# LargeDummyDevice register map
File version: 1.0
Registers are 32-bit, read-write, no defined reset value unless marked. A register's access mark holds for its fields unless they carry their own. Offsets are from the block's base; [hi:lo] are bit positions.

## PERIPHERAL_91
Base 0x4005A000
0x04 REG_1 — Register 1
  [34:30] FIELD_7, [28:24] FIELD_5, [26:24] FIELD_14, [24:20] FIELD_3, [23:20] FIELD_4, [21:20] FIELD_15, [23:20] FIELD_17, [20:18] FIELD_2, [22:18] FIELD_6, [18:17] FIELD_16, [21:17] FIELD_18, [20:16] FIELD_19, [16:15] FIELD_10, [15:11] FIELD_1, [7:6] FIELD_8, [6] FIELD_9, [6] FIELD_12, [8:4] FIELD_13, [3:2] FIELD_11
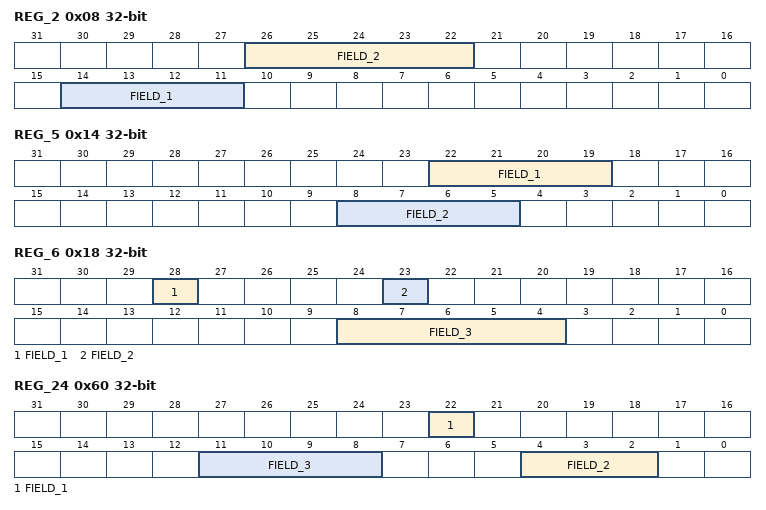
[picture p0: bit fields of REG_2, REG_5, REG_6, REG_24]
0x08 REG_2 — Register 2
  [26:22] FIELD_2, [14:11] FIELD_1
0x0C REG_3 — Register 3
  [31:30] FIELD_19, [31:29] FIELD_10, [30:29] FIELD_22, [29:27] FIELD_21, [24:21] FIELD_11, [25:21] FIELD_13, [21:20] FIELD_3, [18:16] FIELD_1, [16] FIELD_18, [14] FIELD_6, [13] FIELD_9, [12] FIELD_12, [13:9] FIELD_20, [12:8] FIELD_2, [6] FIELD_4, [8:6] FIELD_7, [7:6] FIELD_8, [5] FIELD_16, [5:4] FIELD_14, [2:1] FIELD_15, [4:1] FIELD_17, [4:0] FIELD_5
0x10 REG_4 — Register 4
  [34:30] FIELD_2, [32:29] FIELD_7, [32:29] FIELD_15, [30:27] FIELD_9, [26] FIELD_11, [27:25] FIELD_8, [22:18] FIELD_1, [20:16] FIELD_10, [16:15] FIELD_3, [15:14] FIELD_4, [14] FIELD_12, [13:12] FIELD_6, [3] FIELD_5, [7:3] FIELD_13, [2:1] FIELD_14
0x14 REG_5 — Register 5
  [22:19] FIELD_1, [8:5] FIELD_2
0x18 REG_6 — Register 6
  [28] FIELD_1, [23] FIELD_2, [8:4] FIELD_3
0x1C REG_7 — Register 7
  [32:31] FIELD_3, [31:29] FIELD_6, [28:27] FIELD_5, [29:25] FIELD_12, [21] FIELD_2, [18:17] FIELD_1, [12] FIELD_11, [10] FIELD_4, [14:10] FIELD_8, [10] FIELD_9, [5:1] FIELD_10, [1:0] FIELD_7
0x20 REG_8 — Register 8
  [34:31] FIELD_5, [29:28] FIELD_14, [32:28] FIELD_22, [26] FIELD_4, [25:22] FIELD_11, [25:21] FIELD_15, [23:19] FIELD_20, [21:17] FIELD_1, [15] FIELD_18, [19:15] FIELD_21, [16:12] FIELD_2, [13:12] FIELD_25, [13:11] FIELD_6, [13:11] FIELD_13, [13:10] FIELD_12, [11:10] FIELD_23, [10:8] FIELD_16, [8:6] FIELD_7, [5] FIELD_8, [5:4] FIELD_24, [4:3] FIELD_9, [4:3] FIELD_10, [5:3] FIELD_17, [4:1] FIELD_19, [4:0] FIELD_3
0x24 REG_9 — Register 9
  [29:28] FIELD_5, [28:27] FIELD_14, [24] FIELD_2, [27:24] FIELD_12, [24:22] FIELD_1, [21] FIELD_7, [21:20] FIELD_11, [22:20] FIELD_15, [21:19] FIELD_13, [21:18] FIELD_6, [18] FIELD_17, [18:17] FIELD_9, [15:11] FIELD_8, [12:11] FIELD_10, [12:10] FIELD_16, [5:3] FIELD_3, [5:2] FIELD_4
0x28 REG_10 — Register 10
  [28] FIELD_3, [27:24] FIELD_1, [16:15] FIELD_5, [14:10] FIELD_2, [11:8] FIELD_4
0x2C REG_11 — Register 11
  [32:31] FIELD_16, [31] FIELD_21, [32:28] FIELD_7, [26] FIELD_8, [23:21] FIELD_10, [20:18] FIELD_13, [21:17] FIELD_3, [21:17] FIELD_20, [14:13] FIELD_2, [13] FIELD_12, [13] FIELD_18, [15:12] FIELD_5, [15:12] FIELD_15, [15:11] FIELD_4, [14:10] FIELD_11, [10] FIELD_14, [13:9] FIELD_6, [9:8] FIELD_1, [9:7] FIELD_9, [5] FIELD_17, [5] FIELD_22, [4] FIELD_19
0x30 REG_12 — Register 12
  [32:31] FIELD_4, [32:31] FIELD_14, [31:30] FIELD_5, [29] FIELD_10, [33:29] FIELD_18, [30:26] FIELD_2, [26:24] FIELD_11, [25:23] FIELD_20, [25:22] FIELD_27, [24:21] FIELD_24, [21:19] FIELD_15, [20:19] FIELD_23, [17] FIELD_28, [18:15] FIELD_16, [15:12] FIELD_9, [11:10] FIELD_1, [10:7] FIELD_8, [11:7] FIELD_12, [6] FIELD_3, [8:5] FIELD_7, [6:5] FIELD_13, [8:5] FIELD_22, [8:4] FIELD_17, [7:3] FIELD_26, [3:2] FIELD_21, [4:1] FIELD_19, [4:1] FIELD_25, [0] FIELD_6
0x34 REG_13 — Register 13
  [14] FIELD_1
0x38 REG_14 — Register 14
  [32:29] FIELD_15, [28:25] FIELD_3, [23] FIELD_6, [20] FIELD_11, [22:19] FIELD_4, [16] FIELD_9, [15] FIELD_13, [15:14] FIELD_8, [16:14] FIELD_12, [13] FIELD_5, [12:11] FIELD_7, [8] FIELD_1, [9:8] FIELD_16, [6:5] FIELD_2, [8:5] FIELD_10, [3:2] FIELD_14
0x3C REG_15 — Register 15
  [29:28] FIELD_8, [28:27] FIELD_13, [24:23] FIELD_4, [23] FIELD_7, [21:19] FIELD_15, [18:17] FIELD_3, [19:17] FIELD_12, [21:17] FIELD_14, [20:16] FIELD_5, [16:14] FIELD_9, [15:11] FIELD_10, [10] FIELD_11, [8] FIELD_1, [7:6] FIELD_2, [4:0] FIELD_6
0x40 REG_16 — Register 16
  [31:30] FIELD_1, [33:30] FIELD_11, [30] FIELD_17, [26] FIELD_6, [26:22] FIELD_5, [23:22] FIELD_14, [19:17] FIELD_4, [21:17] FIELD_12, [15:12] FIELD_7, [12:10] FIELD_10, [9] FIELD_15, [12:8] FIELD_8, [9:8] FIELD_16, [8:7] FIELD_3, [11:7] FIELD_13, [4:3] FIELD_2, [5:1] FIELD_9
0x44 REG_17 — Register 17
  [32:31] FIELD_9, [27:26] FIELD_15, [28:25] FIELD_1, [28:24] FIELD_25, [23] FIELD_8, [20] FIELD_10, [21:18] FIELD_24, [19:17] FIELD_23, [18:15] FIELD_11, [19:15] FIELD_17, [15:13] FIELD_4, [12] FIELD_12, [15:11] FIELD_14, [11] FIELD_19, [13:10] FIELD_3, [12:10] FIELD_20, [11:9] FIELD_2, [9] FIELD_5, [10:8] FIELD_7, [9:7] FIELD_21, [7:6] FIELD_16, [8:4] FIELD_6, [6:3] FIELD_13, [4:1] FIELD_18, [1:0] FIELD_22
0x48 REG_18 — Register 18
  [29:28] FIELD_15, [30:27] FIELD_3, [26:25] FIELD_5, [24:23] FIELD_8, [21:17] FIELD_12, [16:15] FIELD_7, [19:15] FIELD_11, [12] FIELD_1, [12:11] FIELD_2, [8] FIELD_4, [10:6] FIELD_6, [9:6] FIELD_9, [7:6] FIELD_14, [8:4] FIELD_13, [4:2] FIELD_10
0x4C REG_19 — Register 19
  [27:26] FIELD_1
0x50 REG_20 — Register 20
  [33:31] FIELD_22, [34:30] FIELD_14, [32:28] FIELD_16, [31:27] FIELD_7, [30:27] FIELD_8, [28:27] FIELD_12, [26:23] FIELD_2, [27:23] FIELD_20, [23:22] FIELD_18, [23:22] FIELD_25, [22:20] FIELD_3, [20] FIELD_6, [23:20] FIELD_9, [19:15] FIELD_24, [14] FIELD_5, [14:13] FIELD_1, [12:11] FIELD_4, [13:9] FIELD_11, [7] FIELD_15, [7] FIELD_21, [7:6] FIELD_13, [8:5] FIELD_23, [6:4] FIELD_19, [3:1] FIELD_17, [2:0] FIELD_10
0x54 REG_21 — Register 21
  [24] FIELD_2, [24:21] FIELD_3, [14:10] FIELD_1
0x58 REG_22 — Register 22
  [34:31] FIELD_13, [31:30] FIELD_17, [33:29] FIELD_12, [29:26] FIELD_6, [30:26] FIELD_18, [28:25] FIELD_2, [26:24] FIELD_7, [26:24] FIELD_9, [25:21] FIELD_3, [19:17] FIELD_11, [19:16] FIELD_16, [14] FIELD_1, [16:12] FIELD_5, [11:10] FIELD_14, [10:6] FIELD_19, [2:1] FIELD_8, [0] FIELD_4, [0] FIELD_10, [3:0] FIELD_15
0x5C REG_23 — Register 23
  [30:28] FIELD_2, [28:27] FIELD_5, [30:27] FIELD_10, [29:25] FIELD_13, [25:21] FIELD_9, [21:20] FIELD_7, [24:20] FIELD_17, [20] FIELD_22, [18] FIELD_8, [18] FIELD_23, [12] FIELD_19, [14:11] FIELD_1, [13:9] FIELD_14, [11:8] FIELD_6, [6] FIELD_3, [8:6] FIELD_12, [6:5] FIELD_4, [5] FIELD_18, [4] FIELD_11, [6:4] FIELD_16, [8:4] FIELD_21, [7:3] FIELD_20, [2:0] FIELD_15
0x60 REG_24 — Register 24
  [22] FIELD_1, [11:8] FIELD_3, [4:2] FIELD_2
0x64 REG_25 — Register 25
  [32:31] FIELD_1, [31:30] FIELD_14, [32:29] FIELD_8, [32:29] FIELD_20, [28] FIELD_11, [30:28] FIELD_17, [25] FIELD_15, [23:21] FIELD_9, [21] FIELD_10, [22:21] FIELD_19, [25:21] FIELD_22, [23:19] FIELD_4, [20:19] FIELD_12, [19:17] FIELD_2, [21:17] FIELD_25, [18:16] FIELD_3, [15:14] FIELD_5, [14] FIELD_7, [15:12] FIELD_6, [14:12] FIELD_21, [11] FIELD_24, [12:10] FIELD_23, [10:6] FIELD_13, [7:6] FIELD_16, [8:4] FIELD_18
0x68 REG_26 — Register 26
  [34:31] FIELD_2, [33:31] FIELD_9, [30] FIELD_8, [34:30] FIELD_20, [31:27] FIELD_10, [28:25] FIELD_11, [27:24] FIELD_25, [25:23] FIELD_29, [24:20] FIELD_4, [23:19] FIELD_30, [22:18] FIELD_15, [20:18] FIELD_17, [18] FIELD_28, [20:17] FIELD_22, [19:16] FIELD_1, [20:16] FIELD_12, [17:16] FIELD_21, [17:16] FIELD_26, [15] FIELD_6, [14] FIELD_23, [11:10] FIELD_5, [10] FIELD_14, [10:9] FIELD_13, [9:8] FIELD_16, [7:6] FIELD_27, [4] FIELD_18, [2:1] FIELD_3, [5:1] FIELD_24, [1:0] FIELD_7, [3:0] FIELD_19
0x6C REG_27 — Register 27
  [32:30] FIELD_26, [29:28] FIELD_11, [27:25] FIELD_9, [26:25] FIELD_17, [24:23] FIELD_6, [24:23] FIELD_20, [22] FIELD_13, [22:20] FIELD_22, [20:19] FIELD_25, [15] FIELD_14, [18:14] FIELD_18, [13:12] FIELD_4, [15:11] FIELD_10, [11:8] FIELD_7, [9:7] FIELD_5, [10:7] FIELD_15, [10:6] FIELD_1, [7:4] FIELD_2, [7:4] FIELD_8, [7:4] FIELD_12, [4:2] FIELD_24, [5:1] FIELD_3, [2:1] FIELD_16, [2:1] FIELD_19, [0] FIELD_21, [1:0] FIELD_23
0x70 REG_28 — Register 28
  [30] FIELD_11, [26:25] FIELD_15, [25:24] FIELD_1, [25:24] FIELD_7, [25:23] FIELD_5, [23] FIELD_22, [24:21] FIELD_2, [22:21] FIELD_23, [22:20] FIELD_19, [23:19] FIELD_17, [18:17] FIELD_20, [17] FIELD_24, [21:17] FIELD_25, [18:15] FIELD_12, [15:13] FIELD_4, [16:13] FIELD_10, [13:11] FIELD_16, [11:8] FIELD_9, [12:8] FIELD_18, [11:7] FIELD_26, [6:4] FIELD_6, [8:4] FIELD_14, [4:3] FIELD_21, [2] FIELD_3, [3:2] FIELD_13, [5:1] FIELD_8
0x74 REG_29 — Register 29
  [28] FIELD_1, [19:17] FIELD_5, [8] FIELD_4, [12:8] FIELD_6, [7:6] FIELD_3, [6:3] FIELD_9, [4:2] FIELD_2, [2:1] FIELD_7, [0] FIELD_8
0x78 REG_30 — Register 30
  [29:27] FIELD_3, [27:26] FIELD_7, [27:25] FIELD_14, [27:24] FIELD_6, [22:20] FIELD_13, [21:19] FIELD_1, [18:17] FIELD_11, [18:15] FIELD_8, [19:15] FIELD_9, [15:14] FIELD_5, [9:8] FIELD_10, [7:4] FIELD_12, [4:2] FIELD_2, [1:0] FIELD_4
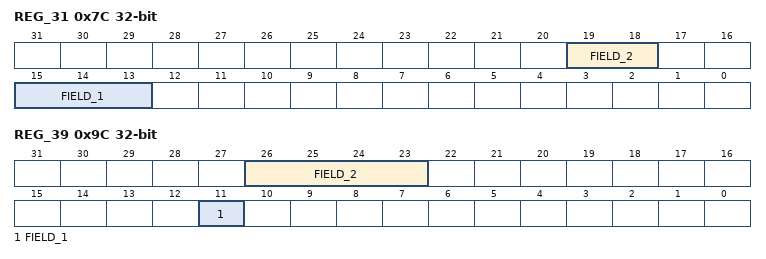
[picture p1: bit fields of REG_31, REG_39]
0x7C REG_31 — Register 31
  [19:18] FIELD_2, [15:13] FIELD_1
0x80 REG_32 — Register 32
  [11:9] FIELD_1
0x84 REG_33 — Register 33
  [30:27] FIELD_9, [30:26] FIELD_11, [29:25] FIELD_25, [26:23] FIELD_3, [25:23] FIELD_24, [26:22] FIELD_5, [24:22] FIELD_7, [23:22] FIELD_15, [20] FIELD_8, [15:13] FIELD_2, [15:13] FIELD_17, [13] FIELD_19, [14:12] FIELD_16, [16:12] FIELD_22, [13:10] FIELD_12, [11:9] FIELD_4, [8] FIELD_20, [7] FIELD_1, [7] FIELD_13, [7:5] FIELD_6, [6:4] FIELD_18, [5:4] FIELD_23, [5:3] FIELD_14, [3:1] FIELD_10, [2:1] FIELD_21
0x88 REG_34 — Register 34
  [34:30] FIELD_12, [32:28] FIELD_23, [31:27] FIELD_14, [30:27] FIELD_19, [30:26] FIELD_27, [26:25] FIELD_9, [26:25] FIELD_18, [25:24] FIELD_25, [25:23] FIELD_4, [24:23] FIELD_16, [26:23] FIELD_21, [27:23] FIELD_24, [25:22] FIELD_1, [23:22] FIELD_17, [26:22] FIELD_22, [23:21] FIELD_3, [22:21] FIELD_15, [20] FIELD_7, [21:19] FIELD_5, [22:18] FIELD_13, [19:17] FIELD_11, [18:16] FIELD_26, [18:14] FIELD_8, [5] FIELD_2, [9:5] FIELD_20, [5:4] FIELD_6, [3:0] FIELD_10
0x8C REG_35 — Register 35
  [33:29] FIELD_13, [32:28] FIELD_20, [28:27] FIELD_17, [29:27] FIELD_18, [29:27] FIELD_22, [25] FIELD_11, [25:24] FIELD_10, [23:22] FIELD_15, [24:22] FIELD_16, [19] FIELD_6, [19] FIELD_8, [21:17] FIELD_3, [16:15] FIELD_12, [16:14] FIELD_2, [17:14] FIELD_4, [17:13] FIELD_23, [15:12] FIELD_9, [12:11] FIELD_19, [12:10] FIELD_14, [9] FIELD_5, [9:7] FIELD_1, [9:7] FIELD_7, [10:7] FIELD_21
0x90 REG_36 — Register 36
  [33:31] FIELD_1, [34:31] FIELD_20, [31:30] FIELD_3, [30:28] FIELD_10, [24:23] FIELD_12, [24:22] FIELD_13, [22:21] FIELD_14, [20:18] FIELD_16, [16] FIELD_8, [16] FIELD_9, [18:14] FIELD_11, [13:11] FIELD_17, [11:10] FIELD_6, [8] FIELD_18, [7] FIELD_4, [10:6] FIELD_2, [8:6] FIELD_7, [6:4] FIELD_5, [6:4] FIELD_15, [5:2] FIELD_19
0x94 REG_37 — Register 37
  [35:31] FIELD_18, [33:29] FIELD_5, [29:26] FIELD_12, [24] FIELD_4, [25:23] FIELD_9, [27:23] FIELD_16, [24:22] FIELD_6, [23:19] FIELD_14, [21:18] FIELD_1, [17:15] FIELD_3, [14:13] FIELD_15, [10] FIELD_13, [10:6] FIELD_8, [10:6] FIELD_11, [7:4] FIELD_17, [5:3] FIELD_2, [2] FIELD_7, [4:1] FIELD_10
0x98 REG_38 — Register 38
  [34:31] FIELD_2, [30:29] FIELD_13, [29:28] FIELD_14, [30:27] FIELD_15, [26] FIELD_11, [24:23] FIELD_1, [24:20] FIELD_9, [19] FIELD_3, [20:18] FIELD_16, [17:16] FIELD_10, [17:15] FIELD_8, [15:14] FIELD_6, [17:13] FIELD_12, [13:11] FIELD_5, [11] FIELD_7, [5] FIELD_4
0x9C REG_39 — Register 39
  [26:23] FIELD_2, [11] FIELD_1
0xA0 REG_40 — Register 40
  [35:31] FIELD_13, [28] FIELD_9, [29:26] FIELD_12, [28:25] FIELD_4, [26:25] FIELD_14, [21:18] FIELD_5, [15] FIELD_2, [16:13] FIELD_6, [10:7] FIELD_7, [8:6] FIELD_11, [7:5] FIELD_8, [4:3] FIELD_1, [7:3] FIELD_3, [4:1] FIELD_10
0xA4 REG_41 — Register 41
  [34:30] FIELD_15, [33:29] FIELD_30, [28] FIELD_17, [30:28] FIELD_18, [29:28] FIELD_25, [31:28] FIELD_29, [26] FIELD_1, [29:26] FIELD_4, [26] FIELD_8, [25] FIELD_7, [28:25] FIELD_27, [24] FIELD_20, [26:23] FIELD_9, [23:21] FIELD_3, [22:20] FIELD_12, [22:19] FIELD_11, [21:17] FIELD_10, [18:17] FIELD_28, [16] FIELD_16, [16:15] FIELD_22, [12:11] FIELD_24, [13:10] FIELD_2, [12:9] FIELD_14, [12:8] FIELD_23, [10:6] FIELD_19, [9:5] FIELD_6, [2] FIELD_5, [3:2] FIELD_13, [5:2] FIELD_21, [2] FIELD_26
0xA8 REG_42 — Register 42
  [35:31] FIELD_17, [30:29] FIELD_2, [29:28] FIELD_29, [30:26] FIELD_10, [29:26] FIELD_13, [26:25] FIELD_19, [28:25] FIELD_22, [28:24] FIELD_16, [25:24] FIELD_31, [24:22] FIELD_23, [22:21] FIELD_1, [24:21] FIELD_7, [22:21] FIELD_21, [21:19] FIELD_18, [20:19] FIELD_28, [18] FIELD_8, [19:18] FIELD_20, [18] FIELD_24, [20:17] FIELD_4, [21:17] FIELD_12, [12] FIELD_15, [12] FIELD_27, [13:9] FIELD_30, [8] FIELD_3, [8:7] FIELD_11, [9:7] FIELD_14, [6:5] FIELD_25, [4:3] FIELD_5, [5:3] FIELD_9, [4:2] FIELD_26, [1] FIELD_6
0xAC REG_43 — Register 43
  [35:31] FIELD_23, [28] FIELD_3, [29:28] FIELD_16, [32:28] FIELD_19, [28:26] FIELD_24, [26:25] FIELD_20, [25:24] FIELD_17, [24:22] FIELD_1, [23:22] FIELD_14, [21:18] FIELD_13, [20:18] FIELD_15, [17] FIELD_6, [17] FIELD_7, [15:14] FIELD_25, [17:13] FIELD_2, [16:12] FIELD_26, [13:11] FIELD_22, [12:10] FIELD_11, [11:10] FIELD_21, [11:9] FIELD_12, [11:8] FIELD_8, [10:6] FIELD_4, [8:5] FIELD_9, [5:4] FIELD_10, [8:4] FIELD_18, [3:0] FIELD_5
0xB0 REG_44 — Register 44
  [31:30] FIELD_8, [32:30] FIELD_9, [33:29] FIELD_24, [29:27] FIELD_15, [28:26] FIELD_5, [26] FIELD_22, [23] FIELD_19, [20:19] FIELD_10, [22:18] FIELD_14, [20:17] FIELD_23, [17:16] FIELD_20, [15] FIELD_4, [19:15] FIELD_17, [16:12] FIELD_1, [12:11] FIELD_6, [11:10] FIELD_7, [13:9] FIELD_21, [8] FIELD_3, [9:8] FIELD_16, [9:7] FIELD_2, [7] FIELD_11, [2] FIELD_18, [4:1] FIELD_13, [2:0] FIELD_12
0xB4 REG_45 — Register 45
  [31:29] FIELD_2, [27:23] FIELD_5, [26:23] FIELD_8, [25:23] FIELD_11, [26:22] FIELD_1, [18:16] FIELD_7, [18:16] FIELD_10, [16:12] FIELD_14, [15:11] FIELD_4, [10] FIELD_9, [10:8] FIELD_15, [8:6] FIELD_3, [8:4] FIELD_13, [4:2] FIELD_18, [1] FIELD_12, [0] FIELD_6, [0] FIELD_16, [3:0] FIELD_17
